# Port_0_1 register map
Vendor: Texas Instruments
Peripheral module from a debugger description file (folder msp430).
Registers are 8-bit, read-write, reset 0x0 unless marked. A register's access mark holds for its fields unless they carry their own. Offsets are as the file gives them; lines under a group give offsets from that group; [hi:lo] are bit positions; {n}, {i} and the like mark numbered series; 'fields as' and 'values as' point back to an identical list; <NAME> marks a mode.

## Port_0
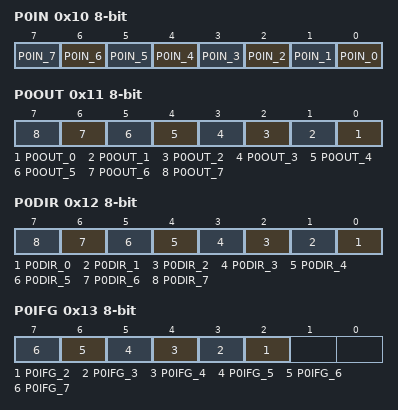
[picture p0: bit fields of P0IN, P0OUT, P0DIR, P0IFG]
0x10 P0IN — Port 0 Input
  [n] P0IN_{n} (n=0..7)
0x11 P0OUT — Port 0 Output
  [n] P0OUT_{n} (n=0..7)
0x12 P0DIR — Port 0 Direction
  [n] P0DIR_{n} (n=0..7)
0x13 P0IFG — Port 0 Interrupt Flag
  [n] P0IFG_{n} (n=2..7)
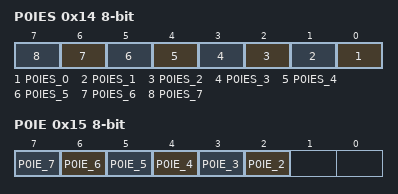
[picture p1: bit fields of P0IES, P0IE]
0x14 P0IES — Port 0 Interrupt Edge Select
  [n] P0IES_{n} (n=0..7)
0x15 P0IE — Port 0 Interrupt Enable
  [n] P0IE_{n} (n=2..7)
